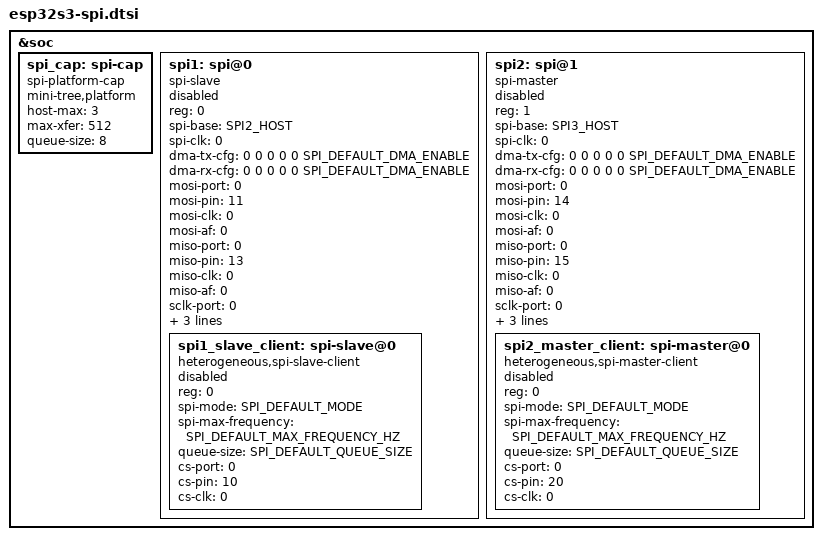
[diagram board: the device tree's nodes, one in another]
// SPDX-License-Identifier: Apache-2.0
/*
 * ESP32-S3 SPI — 对齐 stm32f407-spi.dtsi（另含 slave）
 * 厂商宏直接 #include <hal/spi_types.h>
 */

#include "esp32s3.dtsi"
#include <hal/spi_types.h>
#include <dt-bindings/spi/spi-parameter.h>

&soc {
	spi_cap: spi-cap {
		compatible = "spi-platform-cap";
		mini-tree,platform;
		host-max = <3>;
		max-xfer = <512>;
		queue-size = <8>;
	};

	spi1: spi@0 {
		compatible = "spi-slave";
		reg = <0>;
		#address-cells = <1>;
		#size-cells = <0>;
		spi-base  = <SPI2_HOST>;
		spi-clk   = <0>;
		dma-tx-cfg = <0 0 0 0 0 SPI_DEFAULT_DMA_ENABLE>;
		dma-rx-cfg = <0 0 0 0 0 SPI_DEFAULT_DMA_ENABLE>;

		mosi-port = <0>;
		mosi-pin  = <11>;
		mosi-clk  = <0>;
		mosi-af   = <0>;

		miso-port = <0>;
		miso-pin  = <13>;
		miso-clk  = <0>;
		miso-af   = <0>;

		sclk-port = <0>;
		sclk-pin  = <12>;
		sclk-clk  = <0>;
		sclk-af   = <0>;

		status = "disabled";

		spi1_slave_client: spi-slave@0 {
			compatible = "heterogeneous,spi-slave-client";
			reg = <0>;
			spi-mode = <SPI_DEFAULT_MODE>;
			spi-max-frequency = <SPI_DEFAULT_MAX_FREQUENCY_HZ>;
			queue-size = <SPI_DEFAULT_QUEUE_SIZE>;
			cs-port = <0>;
			cs-pin  = <10>;
			cs-clk  = <0>;
			status = "disabled";
		};
	};

	spi2: spi@1 {
		compatible = "spi-master";
		reg = <1>;
		#address-cells = <1>;
		#size-cells = <0>;
		spi-base  = <SPI3_HOST>;
		spi-clk   = <0>;
		dma-tx-cfg = <0 0 0 0 0 SPI_DEFAULT_DMA_ENABLE>;
		dma-rx-cfg = <0 0 0 0 0 SPI_DEFAULT_DMA_ENABLE>;

		mosi-port = <0>;
		mosi-pin  = <14>;
		mosi-clk  = <0>;
		mosi-af   = <0>;

		miso-port = <0>;
		miso-pin  = <15>;
		miso-clk  = <0>;
		miso-af   = <0>;

		sclk-port = <0>;
		sclk-pin  = <16>;
		sclk-clk  = <0>;
		sclk-af   = <0>;

		status = "disabled";

		spi2_master_client: spi-master@0 {
			compatible = "heterogeneous,spi-master-client";
			reg = <0>;
			#address-cells = <1>;
			#size-cells = <0>;
			spi-mode = <SPI_DEFAULT_MODE>;
			spi-max-frequency = <SPI_DEFAULT_MAX_FREQUENCY_HZ>;
			queue-size = <SPI_DEFAULT_QUEUE_SIZE>;
			cs-port = <0>;
			cs-pin  = <20>;
			cs-clk  = <0>;
			status = "disabled";
		};
	};
};
